VERSION ""

NS_ :

BS_:

BU_: XXX

BO_ 296 NEW_MSG_128: 6 FCW

BO_ 304 NEW_MSG_130: 7 FCW
 SG_ SET_0 : 5|1@0+ (1,0) [0|1] "" XXX

BO_ 352 NEW_MSG_160: 8 FCW

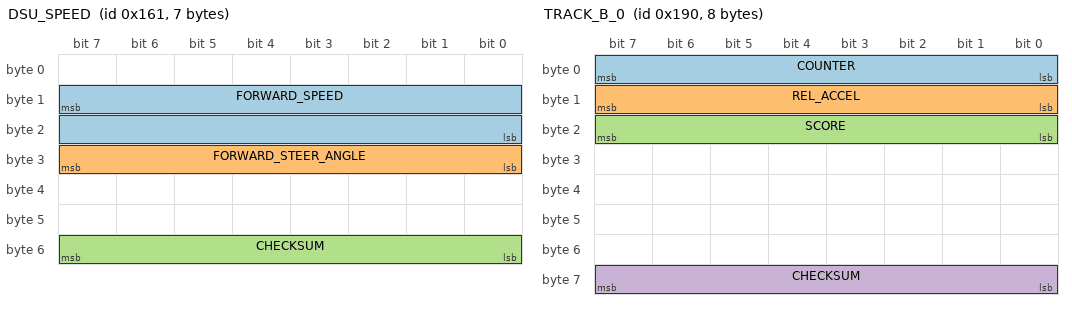
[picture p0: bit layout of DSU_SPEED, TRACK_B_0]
BO_ 353 DSU_SPEED: 7 FCW
 SG_ FORWARD_SPEED : 15|16@0- (0.00390625,-30) [0|255] "km/h" XXX
 SG_ FORWARD_STEER_ANGLE : 31|8@0- (1,0) [0|255] "deg" XXX
 SG_ CHECKSUM : 55|8@0+ (1,0) [0|255] "" XXX

BO_ 384 TRACK_A_0: 8 XXX
 SG_ COUNTER : 7|8@0+ (1,0) [0|255] "" XXX
 SG_ LONG_DIST : 15|15@0+ (0.01,0) [0|300] "m" XXX
 SG_ LAT_DIST : 31|13@0- (0.01,0) [-50|50] "m" XXX
 SG_ NEW_TRACK : 36|1@0+ (1,0) [0|1] "" XXX
 SG_ REL_SPEED : 47|13@0- (0.0125,0) [-100|100] "m/s" XXX
 SG_ VALID : 48|1@0+ (1,0) [0|1] "" XXX
 SG_ NEW_TRACK : 51|1@0+ (1,0) [0|1] "" XXX
 SG_ CHECKSUM : 63|8@0+ (1,0) [0|255] "" XXX

BO_ 385 TRACK_A_1: 8 XXX
 SG_ COUNTER : 7|8@0+ (1,0) [0|255] "" XXX
 SG_ LONG_DIST : 15|15@0+ (0.01,0) [0|300] "m" XXX
 SG_ LAT_DIST : 31|13@0- (0.01,0) [-50|50] "m" XXX
 SG_ NEW_TRACK : 36|1@0+ (1,0) [0|1] "" XXX
 SG_ REL_SPEED : 47|13@0- (0.0125,0) [-100|100] "m/s" XXX
 SG_ VALID : 48|1@0+ (1,0) [0|1] "" XXX
 SG_ NEW_TRACK : 51|1@0+ (1,0) [0|1] "" XXX
 SG_ CHECKSUM : 63|8@0+ (1,0) [0|255] "" XXX

BO_ 386 TRACK_A_2: 8 XXX
 SG_ COUNTER : 7|8@0+ (1,0) [0|255] "" XXX
 SG_ LONG_DIST : 15|15@0+ (0.01,0) [0|300] "m" XXX
 SG_ LAT_DIST : 31|13@0- (0.01,0) [-50|50] "m" XXX
 SG_ NEW_TRACK : 36|1@0+ (1,0) [0|1] "" XXX
 SG_ REL_SPEED : 47|13@0- (0.0125,0) [-100|100] "m/s" XXX
 SG_ VALID : 48|1@0+ (1,0) [0|1] "" XXX
 SG_ NEW_TRACK : 51|1@0+ (1,0) [0|1] "" XXX
 SG_ CHECKSUM : 63|8@0+ (1,0) [0|255] "" XXX

BO_ 387 TRACK_A_3: 8 XXX
 SG_ COUNTER : 7|8@0+ (1,0) [0|255] "" XXX
 SG_ LONG_DIST : 15|15@0+ (0.01,0) [0|300] "m" XXX
 SG_ LAT_DIST : 31|13@0- (0.01,0) [-50|50] "m" XXX
 SG_ NEW_TRACK : 36|1@0+ (1,0) [0|1] "" XXX
 SG_ REL_SPEED : 47|13@0- (0.0125,0) [-100|100] "m/s" XXX
 SG_ VALID : 48|1@0+ (1,0) [0|1] "" XXX
 SG_ NEW_TRACK : 51|1@0+ (1,0) [0|1] "" XXX
 SG_ CHECKSUM : 63|8@0+ (1,0) [0|255] "" XXX

BO_ 388 TRACK_A_4: 8 XXX
 SG_ COUNTER : 7|8@0+ (1,0) [0|255] "" XXX
 SG_ LONG_DIST : 15|15@0+ (0.01,0) [0|300] "m" XXX
 SG_ LAT_DIST : 31|13@0- (0.01,0) [-50|50] "m" XXX
 SG_ NEW_TRACK : 36|1@0+ (1,0) [0|1] "" XXX
 SG_ REL_SPEED : 47|13@0- (0.0125,0) [-100|100] "m/s" XXX
 SG_ VALID : 48|1@0+ (1,0) [0|1] "" XXX
 SG_ NEW_TRACK : 51|1@0+ (1,0) [0|1] "" XXX
 SG_ CHECKSUM : 63|8@0+ (1,0) [0|255] "" XXX

BO_ 389 TRACK_A_5: 8 XXX
 SG_ COUNTER : 7|8@0+ (1,0) [0|255] "" XXX
 SG_ LONG_DIST : 15|15@0+ (0.01,0) [0|300] "m" XXX
 SG_ LAT_DIST : 31|13@0- (0.01,0) [-50|50] "m" XXX
 SG_ NEW_TRACK : 36|1@0+ (1,0) [0|1] "" XXX
 SG_ REL_SPEED : 47|13@0- (0.0125,0) [-100|100] "m/s" XXX
 SG_ VALID : 48|1@0+ (1,0) [0|1] "" XXX
 SG_ NEW_TRACK : 51|1@0+ (1,0) [0|1] "" XXX
 SG_ CHECKSUM : 63|8@0+ (1,0) [0|255] "" XXX

BO_ 390 TRACK_A_6: 8 XXX
 SG_ COUNTER : 7|8@0+ (1,0) [0|255] "" XXX
 SG_ LONG_DIST : 15|15@0+ (0.01,0) [0|300] "m" XXX
 SG_ LAT_DIST : 31|13@0- (0.01,0) [-50|50] "m" XXX
 SG_ NEW_TRACK : 36|1@0+ (1,0) [0|1] "" XXX
 SG_ REL_SPEED : 47|13@0- (0.0125,0) [-100|100] "m/s" XXX
 SG_ VALID : 48|1@0+ (1,0) [0|1] "" XXX
 SG_ NEW_TRACK : 51|1@0+ (1,0) [0|1] "" XXX
 SG_ CHECKSUM : 63|8@0+ (1,0) [0|255] "" XXX

BO_ 391 TRACK_A_7: 8 XXX
 SG_ COUNTER : 7|8@0+ (1,0) [0|255] "" XXX
 SG_ LONG_DIST : 15|15@0+ (0.01,0) [0|300] "m" XXX
 SG_ LAT_DIST : 31|13@0- (0.01,0) [-50|50] "m" XXX
 SG_ NEW_TRACK : 36|1@0+ (1,0) [0|1] "" XXX
 SG_ REL_SPEED : 47|13@0- (0.0125,0) [-100|100] "m/s" XXX
 SG_ VALID : 48|1@0+ (1,0) [0|1] "" XXX
 SG_ NEW_TRACK : 51|1@0+ (1,0) [0|1] "" XXX
 SG_ CHECKSUM : 63|8@0+ (1,0) [0|255] "" XXX

BO_ 392 TRACK_A_8: 8 XXX
 SG_ COUNTER : 7|8@0+ (1,0) [0|255] "" XXX
 SG_ LONG_DIST : 15|15@0+ (0.01,0) [0|300] "m" XXX
 SG_ LAT_DIST : 31|13@0- (0.01,0) [-50|50] "m" XXX
 SG_ NEW_TRACK : 36|1@0+ (1,0) [0|1] "" XXX
 SG_ REL_SPEED : 47|13@0- (0.0125,0) [-100|100] "m/s" XXX
 SG_ VALID : 48|1@0+ (1,0) [0|1] "" XXX
 SG_ NEW_TRACK : 51|1@0+ (1,0) [0|1] "" XXX
 SG_ CHECKSUM : 63|8@0+ (1,0) [0|255] "" XXX

BO_ 393 TRACK_A_9: 8 XXX
 SG_ COUNTER : 7|8@0+ (1,0) [0|255] "" XXX
 SG_ LONG_DIST : 15|15@0+ (0.01,0) [0|300] "m" XXX
 SG_ LAT_DIST : 31|13@0- (0.01,0) [-50|50] "m" XXX
 SG_ NEW_TRACK : 36|1@0+ (1,0) [0|1] "" XXX
 SG_ REL_SPEED : 47|13@0- (0.0125,0) [-100|100] "m/s" XXX
 SG_ VALID : 48|1@0+ (1,0) [0|1] "" XXX
 SG_ NEW_TRACK : 51|1@0+ (1,0) [0|1] "" XXX
 SG_ CHECKSUM : 63|8@0+ (1,0) [0|255] "" XXX

BO_ 394 TRACK_A_10: 8 XXX
 SG_ COUNTER : 7|8@0+ (1,0) [0|255] "" XXX
 SG_ LONG_DIST : 15|15@0+ (0.01,0) [0|300] "m" XXX
 SG_ LAT_DIST : 31|13@0- (0.01,0) [-50|50] "m" XXX
 SG_ NEW_TRACK : 36|1@0+ (1,0) [0|1] "" XXX
 SG_ REL_SPEED : 47|13@0- (0.0125,0) [-100|100] "m/s" XXX
 SG_ VALID : 48|1@0+ (1,0) [0|1] "" XXX
 SG_ NEW_TRACK : 51|1@0+ (1,0) [0|1] "" XXX
 SG_ CHECKSUM : 63|8@0+ (1,0) [0|255] "" XXX

BO_ 395 TRACK_A_11: 8 XXX
 SG_ COUNTER : 7|8@0+ (1,0) [0|255] "" XXX
 SG_ LONG_DIST : 15|15@0+ (0.01,0) [0|300] "m" XXX
 SG_ LAT_DIST : 31|13@0- (0.01,0) [-50|50] "m" XXX
 SG_ NEW_TRACK : 36|1@0+ (1,0) [0|1] "" XXX
 SG_ REL_SPEED : 47|13@0- (0.0125,0) [-100|100] "m/s" XXX
 SG_ VALID : 48|1@0+ (1,0) [0|1] "" XXX
 SG_ NEW_TRACK : 51|1@0+ (1,0) [0|1] "" XXX
 SG_ CHECKSUM : 63|8@0+ (1,0) [0|255] "" XXX

BO_ 396 TRACK_A_12: 8 XXX
 SG_ COUNTER : 7|8@0+ (1,0) [0|255] "" XXX
 SG_ LONG_DIST : 15|15@0+ (0.01,0) [0|300] "m" XXX
 SG_ LAT_DIST : 31|13@0- (0.01,0) [-50|50] "m" XXX
 SG_ NEW_TRACK : 36|1@0+ (1,0) [0|1] "" XXX
 SG_ REL_SPEED : 47|13@0- (0.0125,0) [-100|100] "m/s" XXX
 SG_ VALID : 48|1@0+ (1,0) [0|1] "" XXX
 SG_ NEW_TRACK : 51|1@0+ (1,0) [0|1] "" XXX
 SG_ CHECKSUM : 63|8@0+ (1,0) [0|255] "" XXX

BO_ 397 TRACK_A_13: 8 XXX
 SG_ COUNTER : 7|8@0+ (1,0) [0|255] "" XXX
 SG_ LONG_DIST : 15|15@0+ (0.01,0) [0|300] "m" XXX
 SG_ LAT_DIST : 31|13@0- (0.01,0) [-50|50] "m" XXX
 SG_ NEW_TRACK : 36|1@0+ (1,0) [0|1] "" XXX
 SG_ REL_SPEED : 47|13@0- (0.0125,0) [-100|100] "m/s" XXX
 SG_ VALID : 48|1@0+ (1,0) [0|1] "" XXX
 SG_ NEW_TRACK : 51|1@0+ (1,0) [0|1] "" XXX
 SG_ CHECKSUM : 63|8@0+ (1,0) [0|255] "" XXX

BO_ 398 TRACK_A_14: 8 XXX
 SG_ COUNTER : 7|8@0+ (1,0) [0|255] "" XXX
 SG_ LONG_DIST : 15|15@0+ (0.01,0) [0|300] "m" XXX
 SG_ LAT_DIST : 31|13@0- (0.01,0) [-50|50] "m" XXX
 SG_ NEW_TRACK : 36|1@0+ (1,0) [0|1] "" XXX
 SG_ REL_SPEED : 47|13@0- (0.0125,0) [-100|100] "m/s" XXX
 SG_ VALID : 48|1@0+ (1,0) [0|1] "" XXX
 SG_ NEW_TRACK : 51|1@0+ (1,0) [0|1] "" XXX
 SG_ CHECKSUM : 63|8@0+ (1,0) [0|255] "" XXX

BO_ 399 TRACK_A_15: 8 XXX
 SG_ COUNTER : 7|8@0+ (1,0) [0|255] "" XXX
 SG_ LONG_DIST : 15|15@0+ (0.01,0) [0|300] "m" XXX
 SG_ LAT_DIST : 31|13@0- (0.01,0) [-50|50] "m" XXX
 SG_ NEW_TRACK : 36|1@0+ (1,0) [0|1] "" XXX
 SG_ REL_SPEED : 47|13@0- (0.0125,0) [-100|100] "m/s" XXX
 SG_ VALID : 48|1@0+ (1,0) [0|1] "" XXX
 SG_ NEW_TRACK : 51|1@0+ (1,0) [0|1] "" XXX
 SG_ CHECKSUM : 63|8@0+ (1,0) [0|255] "" XXX

BO_ 400 TRACK_B_0: 8 XXX
 SG_ COUNTER : 7|8@0+ (1,0) [0|255] "" XXX
 SG_ REL_ACCEL : 15|8@0- (0.5,0) [-64|63] "" XXX
 SG_ SCORE : 23|8@0+ (1,0) [0|100] "" XXX
 SG_ CHECKSUM : 63|8@0+ (1,0) [0|255] "" XXX

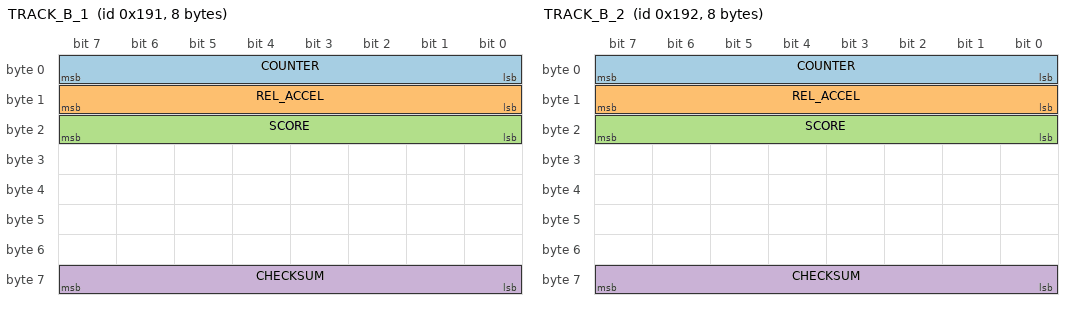
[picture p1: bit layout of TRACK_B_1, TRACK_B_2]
BO_ 401 TRACK_B_1: 8 XXX
 SG_ COUNTER : 7|8@0+ (1,0) [0|255] "" XXX
 SG_ REL_ACCEL : 15|8@0- (0.5,0) [-64|63] "" XXX
 SG_ SCORE : 23|8@0+ (1,0) [0|100] "" XXX
 SG_ CHECKSUM : 63|8@0+ (1,0) [0|255] "" XXX

BO_ 402 TRACK_B_2: 8 XXX
 SG_ COUNTER : 7|8@0+ (1,0) [0|255] "" XXX
 SG_ REL_ACCEL : 15|8@0- (0.5,0) [-64|63] "" XXX
 SG_ SCORE : 23|8@0+ (1,0) [0|100] "" XXX
 SG_ CHECKSUM : 63|8@0+ (1,0) [0|255] "" XXX

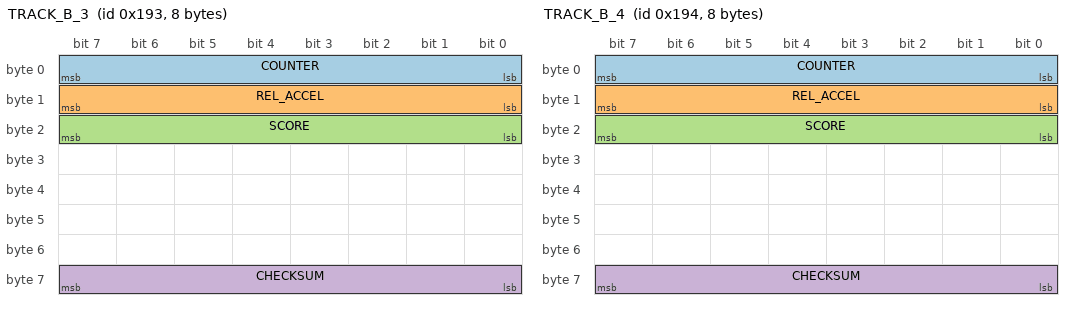
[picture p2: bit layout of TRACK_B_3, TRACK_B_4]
BO_ 403 TRACK_B_3: 8 XXX
 SG_ COUNTER : 7|8@0+ (1,0) [0|255] "" XXX
 SG_ REL_ACCEL : 15|8@0- (0.5,0) [-64|63] "" XXX
 SG_ SCORE : 23|8@0+ (1,0) [0|100] "" XXX
 SG_ CHECKSUM : 63|8@0+ (1,0) [0|255] "" XXX

BO_ 404 TRACK_B_4: 8 XXX
 SG_ COUNTER : 7|8@0+ (1,0) [0|255] "" XXX
 SG_ REL_ACCEL : 15|8@0- (0.5,0) [-64|63] "" XXX
 SG_ SCORE : 23|8@0+ (1,0) [0|100] "" XXX
 SG_ CHECKSUM : 63|8@0+ (1,0) [0|255] "" XXX

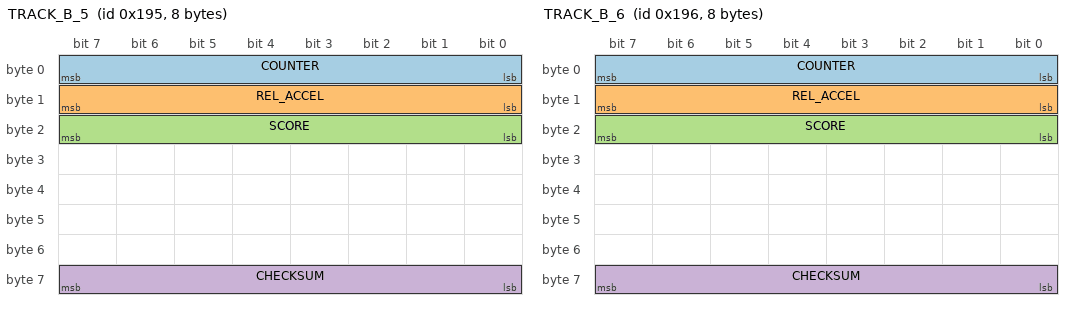
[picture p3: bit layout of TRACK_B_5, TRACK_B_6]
BO_ 405 TRACK_B_5: 8 XXX
 SG_ COUNTER : 7|8@0+ (1,0) [0|255] "" XXX
 SG_ REL_ACCEL : 15|8@0- (0.5,0) [-64|63] "" XXX
 SG_ SCORE : 23|8@0+ (1,0) [0|100] "" XXX
 SG_ CHECKSUM : 63|8@0+ (1,0) [0|255] "" XXX

BO_ 406 TRACK_B_6: 8 XXX
 SG_ COUNTER : 7|8@0+ (1,0) [0|255] "" XXX
 SG_ REL_ACCEL : 15|8@0- (0.5,0) [-64|63] "" XXX
 SG_ SCORE : 23|8@0+ (1,0) [0|100] "" XXX
 SG_ CHECKSUM : 63|8@0+ (1,0) [0|255] "" XXX

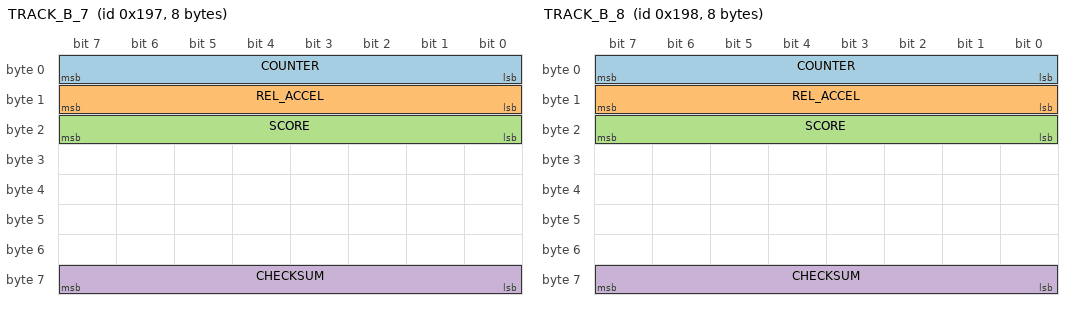
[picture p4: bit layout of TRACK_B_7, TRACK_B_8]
BO_ 407 TRACK_B_7: 8 XXX
 SG_ COUNTER : 7|8@0+ (1,0) [0|255] "" XXX
 SG_ REL_ACCEL : 15|8@0- (0.5,0) [-64|63] "" XXX
 SG_ SCORE : 23|8@0+ (1,0) [0|100] "" XXX
 SG_ CHECKSUM : 63|8@0+ (1,0) [0|255] "" XXX

BO_ 408 TRACK_B_8: 8 XXX
 SG_ COUNTER : 7|8@0+ (1,0) [0|255] "" XXX
 SG_ REL_ACCEL : 15|8@0- (0.5,0) [-64|63] "" XXX
 SG_ SCORE : 23|8@0+ (1,0) [0|100] "" XXX
 SG_ CHECKSUM : 63|8@0+ (1,0) [0|255] "" XXX

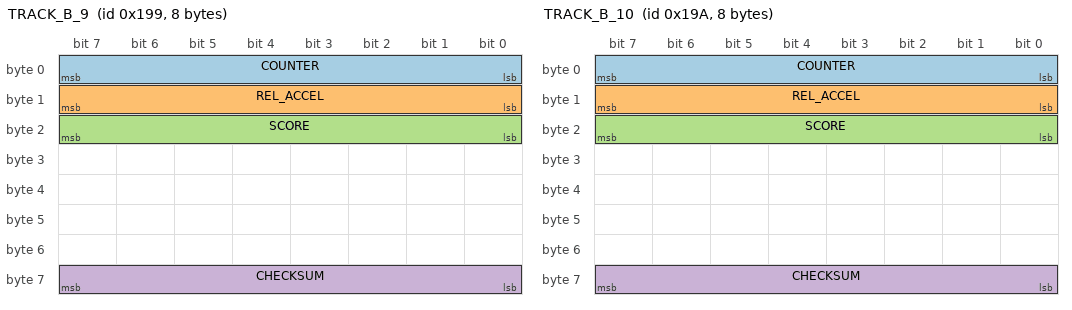
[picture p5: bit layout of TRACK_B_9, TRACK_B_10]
BO_ 409 TRACK_B_9: 8 XXX
 SG_ COUNTER : 7|8@0+ (1,0) [0|255] "" XXX
 SG_ REL_ACCEL : 15|8@0- (0.5,0) [-64|63] "" XXX
 SG_ SCORE : 23|8@0+ (1,0) [0|100] "" XXX
 SG_ CHECKSUM : 63|8@0+ (1,0) [0|255] "" XXX

BO_ 410 TRACK_B_10: 8 XXX
 SG_ COUNTER : 7|8@0+ (1,0) [0|255] "" XXX
 SG_ REL_ACCEL : 15|8@0- (0.5,0) [-64|63] "" XXX
 SG_ SCORE : 23|8@0+ (1,0) [0|100] "" XXX
 SG_ CHECKSUM : 63|8@0+ (1,0) [0|255] "" XXX

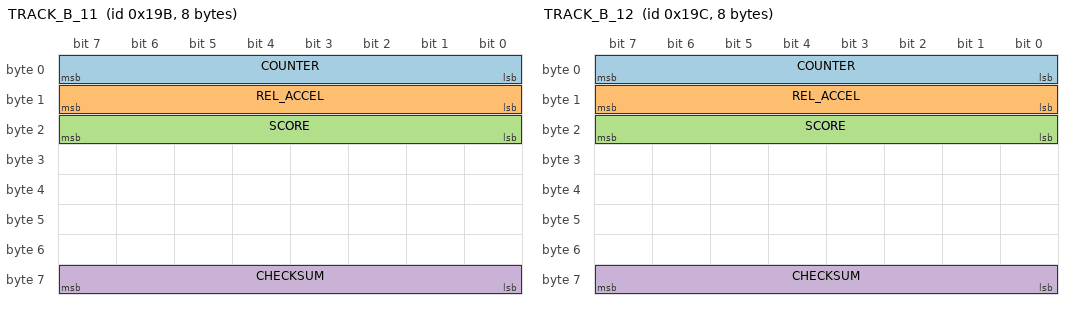
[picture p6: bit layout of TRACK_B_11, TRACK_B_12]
BO_ 411 TRACK_B_11: 8 XXX
 SG_ COUNTER : 7|8@0+ (1,0) [0|255] "" XXX
 SG_ REL_ACCEL : 15|8@0- (0.5,0) [-64|63] "" XXX
 SG_ SCORE : 23|8@0+ (1,0) [0|100] "" XXX
 SG_ CHECKSUM : 63|8@0+ (1,0) [0|255] "" XXX

BO_ 412 TRACK_B_12: 8 XXX
 SG_ COUNTER : 7|8@0+ (1,0) [0|255] "" XXX
 SG_ REL_ACCEL : 15|8@0- (0.5,0) [-64|63] "" XXX
 SG_ SCORE : 23|8@0+ (1,0) [0|100] "" XXX
 SG_ CHECKSUM : 63|8@0+ (1,0) [0|255] "" XXX

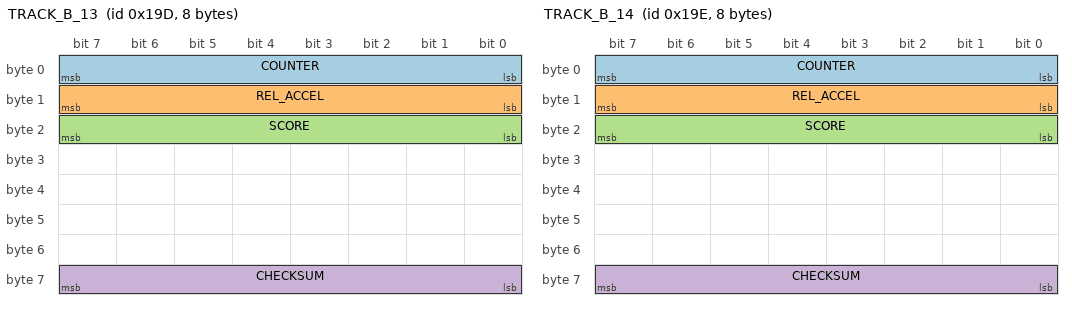
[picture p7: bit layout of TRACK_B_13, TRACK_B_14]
BO_ 413 TRACK_B_13: 8 XXX
 SG_ COUNTER : 7|8@0+ (1,0) [0|255] "" XXX
 SG_ REL_ACCEL : 15|8@0- (0.5,0) [-64|63] "" XXX
 SG_ SCORE : 23|8@0+ (1,0) [0|100] "" XXX
 SG_ CHECKSUM : 63|8@0+ (1,0) [0|255] "" XXX

BO_ 414 TRACK_B_14: 8 XXX
 SG_ COUNTER : 7|8@0+ (1,0) [0|255] "" XXX
 SG_ REL_ACCEL : 15|8@0- (0.5,0) [-64|63] "" XXX
 SG_ SCORE : 23|8@0+ (1,0) [0|100] "" XXX
 SG_ CHECKSUM : 63|8@0+ (1,0) [0|255] "" XXX

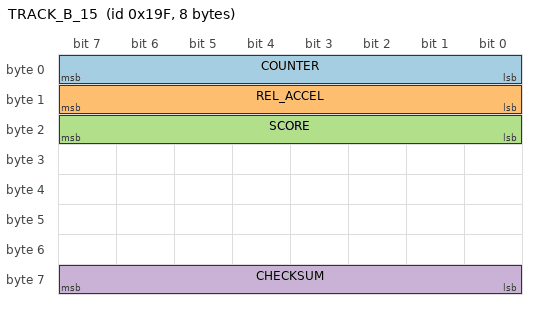
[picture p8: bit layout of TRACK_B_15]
BO_ 415 TRACK_B_15: 8 XXX
 SG_ COUNTER : 7|8@0+ (1,0) [0|255] "" XXX
 SG_ REL_ACCEL : 15|8@0- (0.5,0) [-64|63] "" XXX
 SG_ SCORE : 23|8@0+ (1,0) [0|100] "" XXX
 SG_ CHECKSUM : 63|8@0+ (1,0) [0|255] "" XXX

BO_ 576 NEW_MSG_240: 8 FCW
 SG_ COUNTER : 7|3@0+ (1,0) [0|1] "" XXX

BO_ 577 NEW_MSG_241: 8 FCW
 SG_ COUNTER : 7|3@0+ (1,0) [0|1] "" XXX

BO_ 578 NEW_MSG_242: 8 FCW
 SG_ COUNTER : 7|3@0+ (1,0) [0|1] "" XXX

BO_ 579 NEW_MSG_243: 8 FCW
 SG_ COUNTER : 7|3@0+ (1,0) [0|1] "" XXX

BO_ 580 NEW_MSG_244: 8 FCW
 SG_ COUNTER : 7|3@0+ (1,0) [0|1] "" XXX

BO_ 581 NEW_MSG_245: 8 FCW
 SG_ COUNTER : 7|3@0+ (1,0) [0|1] "" XXX

BO_ 582 NEW_MSG_246: 8 FCW
 SG_ COUNTER : 7|3@0+ (1,0) [0|1] "" XXX

BO_ 583 NEW_MSG_247: 8 FCW
 SG_ COUNTER : 7|3@0+ (1,0) [0|1] "" XXX

BO_ 584 NEW_MSG_248: 8 FCW
 SG_ COUNTER : 7|3@0+ (1,0) [0|1] "" XXX

BO_ 1088 NEW_MSG_440: 8 FCW

BO_ 1089 NEW_MSG_441: 8 FCW
